# R7FA2A2AD register map
Vendor: Renesas Electronics Corporation; Series: RA2A2; File version: 1.20.02
CPU: CM23 r1p0, little endian, MPU, no FPU, VTOR, 2 interrupt priority bits, 32 interrupts
Registers are 8-bit, read-write, reset 0x0 unless marked. A register's access mark holds for its fields unless they carry their own. Offsets are from the block's base; [hi:lo] are bit positions; {n}, {i} and the like mark numbered series.

## SLCDC — Segment LCD Controller
Base 0x40082000
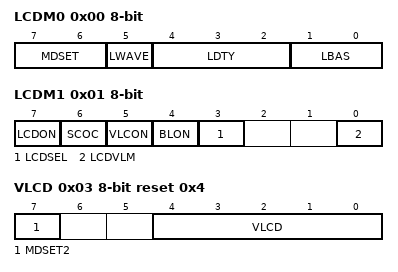
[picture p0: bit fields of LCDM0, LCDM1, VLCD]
0x00 LCDM0 — LCD Mode Register 0
  [7:6] MDSET — LCD Drive Voltage Generator Select
    0=External resistance division method; 1=Internal voltage boosting method; 2=Capacitor split method; 3=Setting prohibited
  [5] LWAVE — LCD Display Waveform Select
    0=Waveform A; 1=Waveform B
  [4:2] LDTY — Time Slice of LCD Display Select
    0=Static; 1=2-time slice; 2=3-time slice; 3=4-time slice; 4=6-time slice; 5=8-time slice; other=Others (Setting prohibited)
  [1:0] LBAS — LCD Display Bias Method Select
    0=1/2 bias method; 1=1/3 bias method; 2=1/4 bias method; 3=Setting prohibited
0x01 LCDM1 — LCD Mode Register 1
  [7] LCDON — LCD Display Enable/Disable
    0=Display off; 1=Display on
  [6] SCOC — LCD Display Enable/Disable
    0=Output ground level to segment/common pin; 1=Display data to segment/common pin
  [5] VLCON — Voltage Boost Circuit or Capacitor Split Circuit Operation Enable/Disable
    0=Disable voltage boost circuit or capacitor split circuit operation; 1=Enable voltage boost circuit or capacitor split circuit operation
  [4] BLON — Alternately Display A-pattern and B-pattern Area Data (blinking display) Control
    0=Alternately display A-pattern and B-pattern area data (blinking display) disabled; 1=Alternately display A-pattern and B-pattern area data (blinking display corresponding to the periodic interrupt (RTC_PRD) timing of the Realtime Clock (RTC))
  [3] LCDSEL — Display Area Data Selection
    0=Display an A-pattern area data (lower 4 bits of LCD display data register); 1=Display a B-pattern area data (higher 4 bits of LCD display data register)
  [0] LCDVLM — Voltage Boosting Pin Initial Value Switching Control
    0=Set when VCC ≥ 2.7 V; 1=Set when VCC ≤ 4.2 V
0x02 LCDC0 — LCD Clock Control Register 0
  [5:0] LCDC0 — LCD Clock (LCDCL) Setting
    {v}=(SOSC)/{v+21} or (LOCO)/{v+21} (v=1..8); 9=(SOSC)/210 or (LOCO)/210; 17=(MOSC)/28, (HOCO)/28, or (MOCO)/28; 18=(MOSC)/29, (HOCO)/29, or (MOCO)/29; {v}=(MOSC)/{v+191}, (HOCO)/{v+191}, or (MOCO)/{v+191} (v=19..27); 43=(MOSC)/219, (HOCO)/219, or (MOCO)/219; 59=(MOSC)/220, (HOCO)/220, or (MOCO)/220; other=Others (Settings are prohibited)
0x03 VLCD reset 0x4 — LCD Boost Level Control Register
  [7] MDSET2 — Reference Voltage Selection
    0=External resistance division method or VL1 reference mode of internal voltage boosting method or VCC reference mode of capacitor split method; 1=VL2 reference mode of internal voltage boosting method or VL4 reference mode of capacitor split method
  [4:0] VLCD — Reference Voltage Select (Contrast Adjustment)
    4=1.01 V (VL1 reference voltage) 2.02 V (VL2 reference voltage); 5=1.04 V (VL1 reference voltage) 2.09 V (VL2 reference voltage); 6=1.07 V (VL1 reference voltage) 2.16 V (VL2 reference voltage); 7=1.11 V (VL1 reference voltage) 2.22 V (VL2 reference voltage); 8=1.14 V (VL1 reference voltage) 2.29 V (VL2 reference voltage); 9=1.17 V (VL1 reference voltage) 2.36 V (VL2 reference voltage); 10=1.21 V (VL1 reference voltage) 2.42 V (VL2 reference voltage); 11=1.24 V (VL1 reference voltage) 2.49 V (VL2 reference voltage); 12=1.27 V (VL1 reference voltage) 2.56 V (VL2 reference voltage); 13=1.31 V (VL1 reference voltage) 2.62 V (VL2 reference voltage); 14=1.34 V (VL1 reference voltage) 2.69 V (VL2 reference voltage); 15=1.37 V (VL1 reference voltage) 2.76 V (VL2 reference voltage); 16=1.40 V (VL1 reference voltage) 2.82 V (VL2 reference voltage); 17=1.44 V (VL1 reference voltage) 2.89 V (VL2 reference voltage); 18=1.47 V (VL1 reference voltage) 2.96 V (VL2 reference voltage); 19=1.50 V (VL1 reference voltage) 3.02 V (VL2 reference voltage); 20=1.54 V (VL1 reference voltage) 3.09 V (VL2 reference voltage); 21=1.57 V (VL1 reference voltage) 3.15 V (VL2 reference voltage); 22=1.60 V (VL1 reference voltage) 3.22 V (VL2 reference voltage); 23=1.64 V (VL1 reference voltage) 3.29 V (VL2 reference voltage); 24=1.67 V (VL1 reference voltage) 3.35 V (VL2 reference voltage); 25=1.70 V (VL1 reference voltage) 3.42 V (VL2 reference voltage); 26=1.74 V (VL1 reference voltage) 3.49 V (VL2 reference voltage); other=Others (Setting prohibited)
{0x100+i} SEG[{i}] (i=0..44) — LCD Display Data Register {i}
